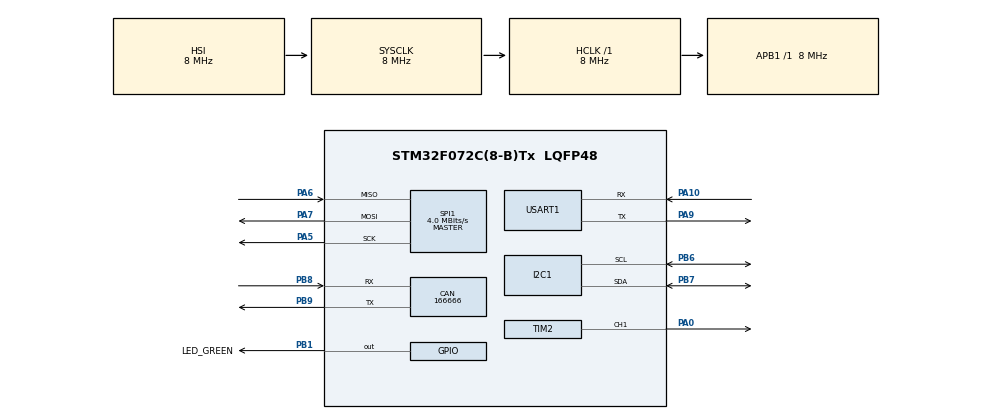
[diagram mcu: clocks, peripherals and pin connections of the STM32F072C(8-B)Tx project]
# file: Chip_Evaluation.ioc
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CAN.CalculateBaudRate=166666
CAN.CalculateTimeBit=6000
CAN.CalculateTimeQuantum=2000.0
I2C1.Timing=0x00201D2B
Mcu.Family=STM32F0
Mcu.Name=STM32F072C(8-B)Tx
Mcu.Package=LQFP48
PA0.Signal=S_TIM2_CH1_ETR
PA10.Mode=Asynchronous
PA10.Signal=USART1_RX
PA13.Mode=Serial_Wire
PA13.Signal=SYS_SWDIO
PA14.Mode=Serial_Wire
PA14.Signal=SYS_SWCLK
PA5.Mode=Full_Duplex_Master
PA5.Signal=SPI1_SCK
PA6.Mode=Full_Duplex_Master
PA6.Signal=SPI1_MISO
PA7.Mode=Full_Duplex_Master
PA7.Signal=SPI1_MOSI
PA9.Mode=Asynchronous
PA9.Signal=USART1_TX
PB1.GPIO_Label=LED_GREEN
PB1.Signal=GPIO_Output
PB6.Mode=I2C
PB6.Signal=I2C1_SCL
PB7.Mode=I2C
PB7.Signal=I2C1_SDA
PB8.Mode=CAN_Activate
PB8.Signal=CAN_RX
PB9.Mode=CAN_Activate
PB9.Signal=CAN_TX
ProjectManager.HeapSize=0x200
ProjectManager.StackSize=0x400
ProjectManager.TargetToolchain=STM32CubeIDE
RCC.AHBFreq_Value=8000000
RCC.APB1Freq_Value=8000000
RCC.APB1TimFreq_Value=8000000
RCC.HCLKFreq_Value=8000000
RCC.SYSCLKFreq_VALUE=8000000
SH.S_TIM2_CH1_ETR.0=TIM2_CH1,PWM Generation1 CH1
SPI1.BaudRatePrescaler=SPI_BAUDRATEPRESCALER_2
SPI1.CalculateBaudRate=4.0 MBits/s
SPI1.Direction=SPI_DIRECTION_2LINES
SPI1.Mode=SPI_MODE_MASTER
SPI1.VirtualType=VM_MASTER
TIM2.Channel-PWM\ Generation1\ CH1=TIM_CHANNEL_1
TIM2.Period=62499
TIM2.Prescaler=127
TIM2.Pulse-PWM\ Generation1\ CH1=31250
USART1.VirtualMode-Asynchronous=VM_ASYNC
VP_TIM2_VS_ClockSourceINT.Mode=Internal
board=custom

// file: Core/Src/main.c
/* USER CODE BEGIN Header */
/**
  ******************************************************************************
  * @file           : main.c
  * @brief          : Main program body
  ******************************************************************************
  * @attention
  *
  * Copyright (c) 2025 STMicroelectronics.
  * All rights reserved.
  *
  * This software is licensed under terms that can be found in the LICENSE file
  * in the root directory of this software component.
  * If no LICENSE file comes with this software, it is provided AS-IS.
  *
  ******************************************************************************
  */
/* USER CODE END Header */
#include "main.h"

CAN_HandleTypeDef hcan;

I2C_HandleTypeDef hi2c1;

SPI_HandleTypeDef hspi1;

TIM_HandleTypeDef htim2;

UART_HandleTypeDef huart1;

void SystemClock_Config(void);
static void MX_GPIO_Init(void);
static void MX_CAN_Init(void);
static void MX_I2C1_Init(void);
static void MX_SPI1_Init(void);
static void MX_USART1_UART_Init(void);
static void MX_TIM2_Init(void);

int main(void)
{

  /* MCU Configuration--------------------------------------------------------*/

  /* Reset of all peripherals, Initializes the Flash interface and the Systick. */
  HAL_Init();

  /* Configure the system clock */
  SystemClock_Config();

  /* Initialize all configured peripherals */
  MX_GPIO_Init();
  MX_CAN_Init();
  MX_I2C1_Init();
  MX_SPI1_Init();
  MX_USART1_UART_Init();
  MX_TIM2_Init();
  /* USER CODE BEGIN 2 */
  HAL_TIM_PWM_Start(&htim2, TIM_CHANNEL_1); // With this line, the while loop will be empty

  /* USER CODE END 2 */

  /* Infinite loop */
  /* USER CODE BEGIN WHILE */
  while (1)
  {
	HAL_GPIO_TogglePin(LED_GREEN_GPIO_Port, LED_GREEN_Pin);
	HAL_Delay(500);

    /* USER CODE END WHILE */

  }
}

void SystemClock_Config(void)
{
  RCC_OscInitTypeDef RCC_OscInitStruct = {0};
  RCC_ClkInitTypeDef RCC_ClkInitStruct = {0};
  RCC_PeriphCLKInitTypeDef PeriphClkInit = {0};

  /** Initializes the RCC Oscillators according to the specified parameters
  * in the RCC_OscInitTypeDef structure.
  */
  RCC_OscInitStruct.OscillatorType = RCC_OSCILLATORTYPE_HSI;
  RCC_OscInitStruct.HSIState = RCC_HSI_ON;
  RCC_OscInitStruct.HSICalibrationValue = RCC_HSICALIBRATION_DEFAULT;
  RCC_OscInitStruct.PLL.PLLState = RCC_PLL_NONE;
  if (HAL_RCC_OscConfig(&RCC_OscInitStruct) != HAL_OK)
  {
    Error_Handler();
  }

  /** Initializes the CPU, AHB and APB buses clocks
  */
  RCC_ClkInitStruct.ClockType = RCC_CLOCKTYPE_HCLK|RCC_CLOCKTYPE_SYSCLK
                              |RCC_CLOCKTYPE_PCLK1;
  RCC_ClkInitStruct.SYSCLKSource = RCC_SYSCLKSOURCE_HSI;
  RCC_ClkInitStruct.AHBCLKDivider = RCC_SYSCLK_DIV1;
  RCC_ClkInitStruct.APB1CLKDivider = RCC_HCLK_DIV1;

  if (HAL_RCC_ClockConfig(&RCC_ClkInitStruct, FLASH_LATENCY_0) != HAL_OK)
  {
    Error_Handler();
  }
  PeriphClkInit.PeriphClockSelection = RCC_PERIPHCLK_USART1|RCC_PERIPHCLK_I2C1;
  PeriphClkInit.Usart1ClockSelection = RCC_USART1CLKSOURCE_PCLK1;
  PeriphClkInit.I2c1ClockSelection = RCC_I2C1CLKSOURCE_HSI;
  if (HAL_RCCEx_PeriphCLKConfig(&PeriphClkInit) != HAL_OK)
  {
    Error_Handler();
  }
}

static void MX_CAN_Init(void)
{

  hcan.Instance = CAN;
  hcan.Init.Prescaler = 16;
  hcan.Init.Mode = CAN_MODE_NORMAL;
  hcan.Init.SyncJumpWidth = CAN_SJW_1TQ;
  hcan.Init.TimeSeg1 = CAN_BS1_1TQ;
  hcan.Init.TimeSeg2 = CAN_BS2_1TQ;
  hcan.Init.TimeTriggeredMode = DISABLE;
  hcan.Init.AutoBusOff = DISABLE;
  hcan.Init.AutoWakeUp = DISABLE;
  hcan.Init.AutoRetransmission = DISABLE;
  hcan.Init.ReceiveFifoLocked = DISABLE;
  hcan.Init.TransmitFifoPriority = DISABLE;
  if (HAL_CAN_Init(&hcan) != HAL_OK)
  {
    Error_Handler();
  }

}

static void MX_I2C1_Init(void)
{

  hi2c1.Instance = I2C1;
  hi2c1.Init.Timing = 0x00201D2B;
  hi2c1.Init.OwnAddress1 = 0;
  hi2c1.Init.AddressingMode = I2C_ADDRESSINGMODE_7BIT;
  hi2c1.Init.DualAddressMode = I2C_DUALADDRESS_DISABLE;
  hi2c1.Init.OwnAddress2 = 0;
  hi2c1.Init.OwnAddress2Masks = I2C_OA2_NOMASK;
  hi2c1.Init.GeneralCallMode = I2C_GENERALCALL_DISABLE;
  hi2c1.Init.NoStretchMode = I2C_NOSTRETCH_DISABLE;
  if (HAL_I2C_Init(&hi2c1) != HAL_OK)
  {
    Error_Handler();
  }

  /** Configure Analogue filter
  */
  if (HAL_I2CEx_ConfigAnalogFilter(&hi2c1, I2C_ANALOGFILTER_ENABLE) != HAL_OK)
  {
    Error_Handler();
  }

  /** Configure Digital filter
  */
  if (HAL_I2CEx_ConfigDigitalFilter(&hi2c1, 0) != HAL_OK)
  {
    Error_Handler();
  }

}

static void MX_SPI1_Init(void)
{

  /* SPI1 parameter configuration*/
  hspi1.Instance = SPI1;
  hspi1.Init.Mode = SPI_MODE_MASTER;
  hspi1.Init.Direction = SPI_DIRECTION_2LINES;
  hspi1.Init.DataSize = SPI_DATASIZE_4BIT;
  hspi1.Init.CLKPolarity = SPI_POLARITY_LOW;
  hspi1.Init.CLKPhase = SPI_PHASE_1EDGE;
  hspi1.Init.NSS = SPI_NSS_SOFT;
  hspi1.Init.BaudRatePrescaler = SPI_BAUDRATEPRESCALER_2;
  hspi1.Init.FirstBit = SPI_FIRSTBIT_MSB;
  hspi1.Init.TIMode = SPI_TIMODE_DISABLE;
  hspi1.Init.CRCCalculation = SPI_CRCCALCULATION_DISABLE;
  hspi1.Init.CRCPolynomial = 7;
  hspi1.Init.CRCLength = SPI_CRC_LENGTH_DATASIZE;
  hspi1.Init.NSSPMode = SPI_NSS_PULSE_ENABLE;
  if (HAL_SPI_Init(&hspi1) != HAL_OK)
  {
    Error_Handler();
  }

}

static void MX_TIM2_Init(void)
{

  TIM_ClockConfigTypeDef sClockSourceConfig = {0};
  TIM_MasterConfigTypeDef sMasterConfig = {0};
  TIM_OC_InitTypeDef sConfigOC = {0};

  htim2.Instance = TIM2;
  htim2.Init.Prescaler = 127;
  htim2.Init.CounterMode = TIM_COUNTERMODE_UP;
  htim2.Init.Period = 62499;
  htim2.Init.ClockDivision = TIM_CLOCKDIVISION_DIV1;
  htim2.Init.AutoReloadPreload = TIM_AUTORELOAD_PRELOAD_DISABLE;
  if (HAL_TIM_Base_Init(&htim2) != HAL_OK)
  {
    Error_Handler();
  }
  sClockSourceConfig.ClockSource = TIM_CLOCKSOURCE_INTERNAL;
  if (HAL_TIM_ConfigClockSource(&htim2, &sClockSourceConfig) != HAL_OK)
  {
    Error_Handler();
  }
  if (HAL_TIM_PWM_Init(&htim2) != HAL_OK)
  {
    Error_Handler();
  }
  sMasterConfig.MasterOutputTrigger = TIM_TRGO_RESET;
  sMasterConfig.MasterSlaveMode = TIM_MASTERSLAVEMODE_DISABLE;
  if (HAL_TIMEx_MasterConfigSynchronization(&htim2, &sMasterConfig) != HAL_OK)
  {
    Error_Handler();
  }
  sConfigOC.OCMode = TIM_OCMODE_PWM1;
  sConfigOC.Pulse = 31250;
  sConfigOC.OCPolarity = TIM_OCPOLARITY_HIGH;
  sConfigOC.OCFastMode = TIM_OCFAST_DISABLE;
  if (HAL_TIM_PWM_ConfigChannel(&htim2, &sConfigOC, TIM_CHANNEL_1) != HAL_OK)
  {
    Error_Handler();
  }
  HAL_TIM_MspPostInit(&htim2);

}

static void MX_USART1_UART_Init(void)
{

  huart1.Instance = USART1;
  huart1.Init.BaudRate = 38400;
  huart1.Init.WordLength = UART_WORDLENGTH_8B;
  huart1.Init.StopBits = UART_STOPBITS_1;
  huart1.Init.Parity = UART_PARITY_NONE;
  huart1.Init.Mode = UART_MODE_TX_RX;
  huart1.Init.HwFlowCtl = UART_HWCONTROL_NONE;
  huart1.Init.OverSampling = UART_OVERSAMPLING_16;
  huart1.Init.OneBitSampling = UART_ONE_BIT_SAMPLE_DISABLE;
  huart1.AdvancedInit.AdvFeatureInit = UART_ADVFEATURE_NO_INIT;
  if (HAL_UART_Init(&huart1) != HAL_OK)
  {
    Error_Handler();
  }

}

static void MX_GPIO_Init(void)
{
  GPIO_InitTypeDef GPIO_InitStruct = {0};

  /* GPIO Ports Clock Enable */
  __HAL_RCC_GPIOA_CLK_ENABLE();
  __HAL_RCC_GPIOB_CLK_ENABLE();

  /*Configure GPIO pin Output Level */
  HAL_GPIO_WritePin(LED_GREEN_GPIO_Port, LED_GREEN_Pin, GPIO_PIN_RESET);

  /*Configure GPIO pin : LED_GREEN_Pin */
  GPIO_InitStruct.Pin = LED_GREEN_Pin;
  GPIO_InitStruct.Mode = GPIO_MODE_OUTPUT_PP;
  GPIO_InitStruct.Pull = GPIO_NOPULL;
  GPIO_InitStruct.Speed = GPIO_SPEED_FREQ_LOW;
  HAL_GPIO_Init(LED_GREEN_GPIO_Port, &GPIO_InitStruct);

}

void Error_Handler(void)
{
  __disable_irq();
  while (1)
  {
  }
}
